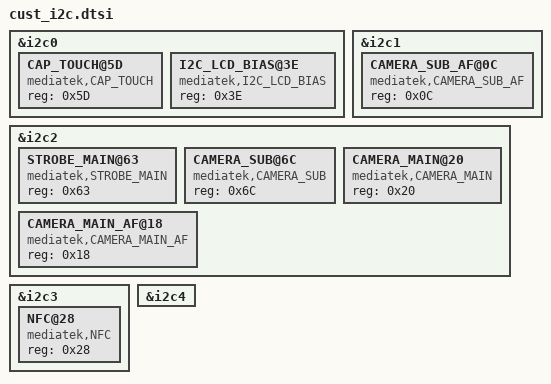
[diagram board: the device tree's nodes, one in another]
/*
 * Generated by MTK SP Drv_CodeGen Version 03.13.6  for MT6755. Copyright MediaTek Inc. (C) 2013.
 * Thu Jul 30 11:48:33 2026
 * Do Not Modify the File.
 */

/*************************
 * I2C DTSI File
*************************/

&i2c0 {
	CAP_TOUCH@5D {
		compatible = "mediatek,CAP_TOUCH";
		reg = <0x5D>;
	};

	I2C_LCD_BIAS@3E {
		compatible = "mediatek,I2C_LCD_BIAS";
		reg = <0x3E>;
	};

};

&i2c1 {
	CAMERA_SUB_AF@0C {
		compatible = "mediatek,CAMERA_SUB_AF";
		reg = <0x0C>;
	};

};

&i2c2 {
	STROBE_MAIN@63 {
		compatible = "mediatek,STROBE_MAIN";
		reg = <0x63>;
	};

	CAMERA_SUB@6C {
		compatible = "mediatek,CAMERA_SUB";
		reg = <0x6C>;
	};

	CAMERA_MAIN@20 {
		compatible = "mediatek,CAMERA_MAIN";
		reg = <0x20>;
	};

	CAMERA_MAIN_AF@18 {
		compatible = "mediatek,CAMERA_MAIN_AF";
		reg = <0x18>;
	};

};

&i2c3 {
	NFC@28 {
		compatible = "mediatek,NFC";
		reg = <0x28>;
	};

};

&i2c4 {
};

